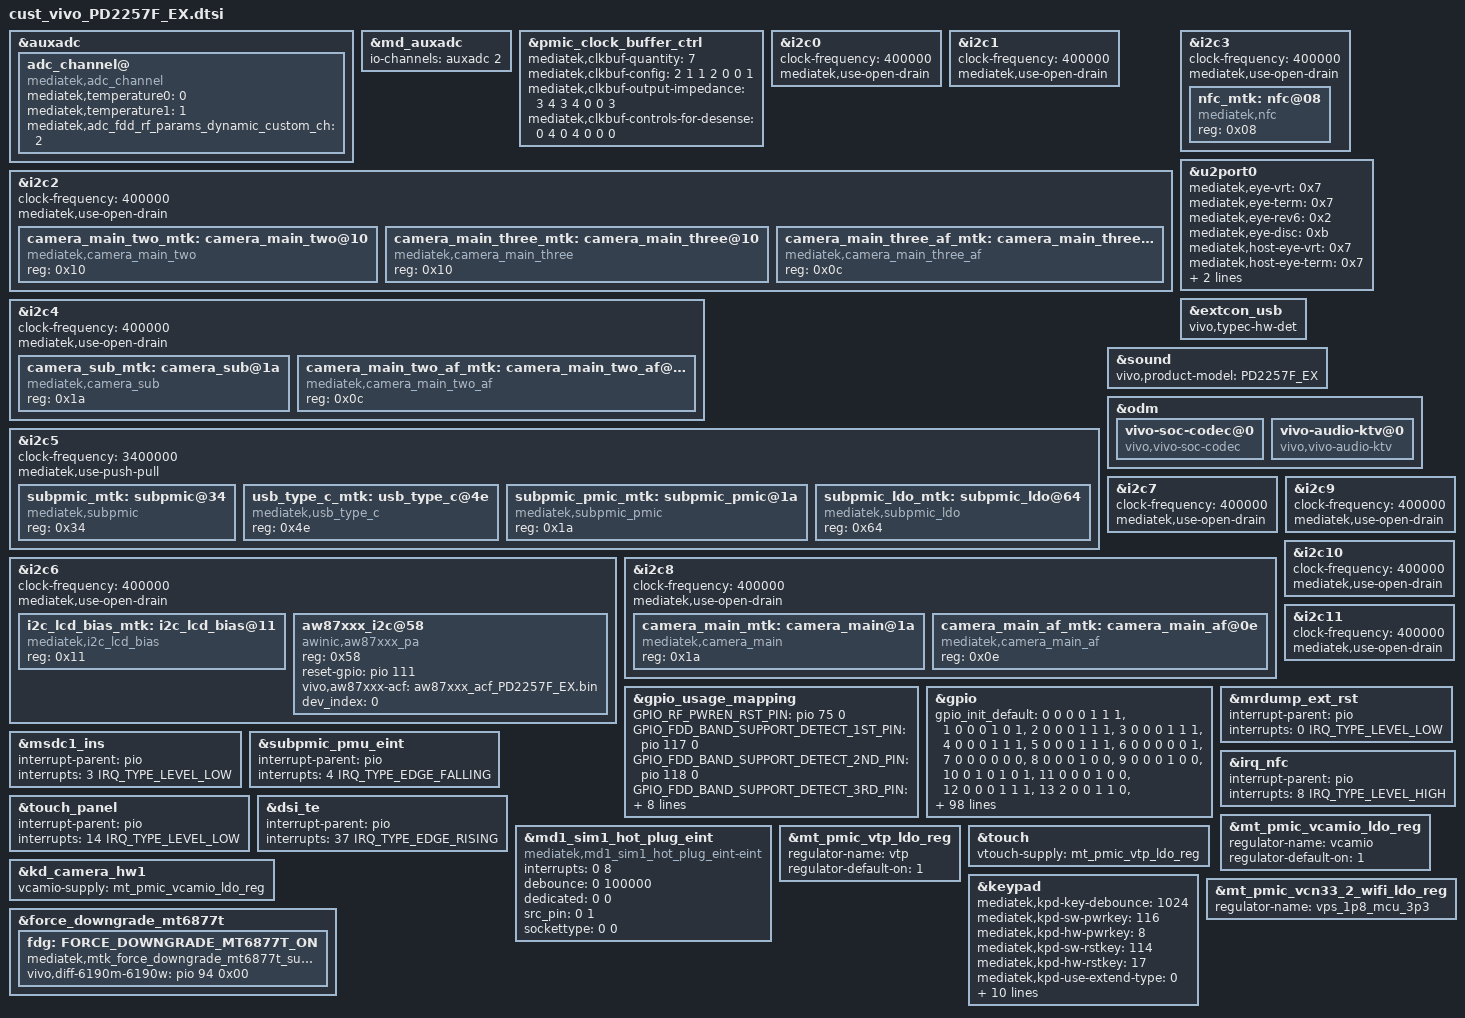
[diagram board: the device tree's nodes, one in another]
/*
	int vbat_mv = batt_volt, vbat_mv_sum = 0, iterm = 0;
 * Generated by MTK SP DrvGen Version: 3.5.160809 for MT6877.
 * 2022-09-20 15:01:34
 * Copyright Mediatek Inc. (c) 2016.
*/

/*************************
 * ADC DTSI File
*************************/
#include <dt-bindings/pinctrl/mt6877-pinfunc.h>

&auxadc {
	adc_channel@ {
		compatible = "mediatek,adc_channel";
		mediatek,temperature0 = <0>;
		mediatek,temperature1 = <1>;
		mediatek,adc_fdd_rf_params_dynamic_custom_ch = <2>;
		status = "okay";
	};
};
&md_auxadc {
	io-channels = <&auxadc 2>;
};


/*************************
 * CLK_BUF DTSI File
*************************/

&pmic_clock_buffer_ctrl {
	mediatek,clkbuf-quantity = <7>;
	mediatek,clkbuf-config = <2 1 1 2 0 0 1>;
	mediatek,clkbuf-output-impedance = <3 4 3 4 0 0 3>;
	mediatek,clkbuf-controls-for-desense = <0 4 0 4 0 0 0>;
	status = "okay";
};


/*************************
 * I2C DTSI File
*************************/

&i2c0 {
	#address-cells = <1>;
	#size-cells = <0>;
	clock-frequency = <400000>;
	mediatek,use-open-drain;
};

&i2c1 {
	#address-cells = <1>;
	#size-cells = <0>;
	clock-frequency = <400000>;
	mediatek,use-open-drain;
};

&i2c2 {
	#address-cells = <1>;
	#size-cells = <0>;
	clock-frequency = <400000>;
	mediatek,use-open-drain;
	camera_main_two_mtk:camera_main_two@10 {
		compatible = "mediatek,camera_main_two";
		reg = <0x10>;
		status = "okay";
	};

	camera_main_three_mtk:camera_main_three@10 {
		compatible = "mediatek,camera_main_three";
		reg = <0x10>;
		status = "okay";
	};

	camera_main_three_af_mtk:camera_main_three_af@0c {
		compatible = "mediatek,camera_main_three_af";
		reg = <0x0c>;
		status = "okay";
	};

};

&i2c3 {
	#address-cells = <1>;
	#size-cells = <0>;
	clock-frequency = <400000>;
	mediatek,use-open-drain;
	nfc_mtk:nfc@08 {
		compatible = "mediatek,nfc";
		reg = <0x08>;
		status = "okay";
	};

};

&i2c4 {
	#address-cells = <1>;
	#size-cells = <0>;
	clock-frequency = <400000>;
	mediatek,use-open-drain;
	camera_sub_mtk:camera_sub@1a {
		compatible = "mediatek,camera_sub";
		reg = <0x1a>;
		status = "okay";
	};

	camera_main_two_af_mtk:camera_main_two_af@0c {
		compatible = "mediatek,camera_main_two_af";
		reg = <0x0c>;
		status = "okay";
	};

};

&i2c5 {
	#address-cells = <1>;
	#size-cells = <0>;
	clock-frequency = <3400000>;
	mediatek,use-push-pull;
	subpmic_mtk:subpmic@34 {
		compatible = "mediatek,subpmic";
		reg = <0x34>;
		status = "okay";
	};

	usb_type_c_mtk:usb_type_c@4e {
		compatible = "mediatek,usb_type_c";
		reg = <0x4e>;
		status = "okay";
	};

	subpmic_pmic_mtk:subpmic_pmic@1a {
		compatible = "mediatek,subpmic_pmic";
		reg = <0x1a>;
		status = "okay";
	};

	subpmic_ldo_mtk:subpmic_ldo@64 {
		compatible = "mediatek,subpmic_ldo";
		reg = <0x64>;
		status = "okay";
	};

};

&i2c6 {
	#address-cells = <1>;
	#size-cells = <0>;
	clock-frequency = <400000>;
	mediatek,use-open-drain;
	i2c_lcd_bias_mtk:i2c_lcd_bias@11 {
		compatible = "mediatek,i2c_lcd_bias";
		reg = <0x11>;
		status = "okay";
	};

};

/* vivo add for usb phy tune begin */
&u2port0 {
	mediatek,eye-vrt = <0x7>;
	mediatek,eye-term = <0x7>;
	mediatek,eye-rev6 = <0x2>;
	mediatek,eye-disc = <0xb>;

	mediatek,host-eye-vrt = <0x7>;
	mediatek,host-eye-term = <0x7>;
	mediatek,host-eye-rev6 = <0x2>;
	mediatek,host-eye-disc = <0xb>;
};

&extcon_usb {
	vivo,typec-hw-det;
};
/* vivo add for usb phy tune end */

/* vivo audio add start */
&sound {
    vivo,product-model = "PD2257F_EX";
};

&odm {
	vivo-soc-codec@0 {
		compatible = "vivo,vivo-soc-codec";
		status = "okay";
	};

	vivo-audio-ktv@0 {
		compatible = "vivo,vivo-audio-ktv";
		status = "okay";
	};
};

&i2c6 {
	aw87xxx_i2c@58 {
		compatible = "awinic,aw87xxx_pa";
		reg = <0x58>;
		reset-gpio = <&pio 111 0>;
		vivo,aw87xxx-acf = "aw87xxx_acf_PD2257F_EX.bin";
		dev_index= <0>;
		status = "okay";
	};
};
/* vivo audio add end */

&i2c7 {
	#address-cells = <1>;
	#size-cells = <0>;
	clock-frequency = <400000>;
	mediatek,use-open-drain;
};

&i2c8 {
	#address-cells = <1>;
	#size-cells = <0>;
	clock-frequency = <400000>;
	mediatek,use-open-drain;
	camera_main_mtk:camera_main@1a {
		compatible = "mediatek,camera_main";
		reg = <0x1a>;
		status = "okay";
	};

	camera_main_af_mtk:camera_main_af@0e {
		compatible = "mediatek,camera_main_af";
		reg = <0x0e>;
		status = "okay";
	};

};

&i2c9 {
	#address-cells = <1>;
	#size-cells = <0>;
	clock-frequency = <400000>;
	mediatek,use-open-drain;
};

&i2c10 {
	#address-cells = <1>;
	#size-cells = <0>;
	clock-frequency = <400000>;
	mediatek,use-open-drain;
};

&i2c11 {
	#address-cells = <1>;
	#size-cells = <0>;
	clock-frequency = <400000>;
	mediatek,use-open-drain;
};



/*************************
 * GPIO DTSI File
*************************/

&gpio_usage_mapping {
	GPIO_RF_PWREN_RST_PIN = <&pio 75 0>;
	GPIO_FDD_BAND_SUPPORT_DETECT_1ST_PIN = <&pio 117 0>;
	GPIO_FDD_BAND_SUPPORT_DETECT_2ND_PIN = <&pio 118 0>;
	GPIO_FDD_BAND_SUPPORT_DETECT_3RD_PIN = <&pio 119 0>;
	GPIO_SIM2_SIO = <&pio 170 0>;
	GPIO_SIM2_SCLK = <&pio 171 0>;
	GPIO_SIM2_SRST = <&pio 172 0>;
	GPIO_SIM1_SRST = <&pio 173 0>;
	GPIO_SIM1_SCLK = <&pio 174 0>;
	GPIO_SIM1_SIO = <&pio 175 0>;
	GPIO_SIM1_HOT_PLUG = <&pio 176 0>;
	//GPIO_SIM2_HOT_PLUG = <&pio 177 0>;
};

&gpio{
	gpio_init_default = <0 0 0 0 1 1 1>,
		<1 0 0 0 1 0 1>,
		<2 0 0 0 1 1 1>,
		<3 0 0 0 1 1 1>,
		<4 0 0 0 1 1 1>,
		<5 0 0 0 1 1 1>,
		<6 0 0 0 0 0 1>,
		<7 0 0 0 0 0 0>,
		<8 0 0 0 1 0 0>,/*pm8008 int*/
		<9 0 0 0 1 0 0>,/*lcm ERR FG*/
		<10 0 1 0 1 0 1>,
		<11 0 0 0 1 0 0>,
		<12 0 0 0 1 1 1>, /* vivo audio modify for headset detect */
		<13 2 0 0 1 1 0>,
		<14 0 0 0 0 0 1>,
		<15 0 1 0 1 0 1>,
		<16 0 1 0 1 0 1>,
		<17 7 0 0 1 0 0>,
		<18 7 0 0 1 1 0>,
		<19 7 0 0 1 0 0>,
		<20 0 0 0 0 0 1>,
		<21 0 1 0 1 0 0>,
		<22 0 0 0 1 0 0>,
		<23 0 0 0 1 0 0>,
		<24 0 0 0 1 1 0>,
		<25 1 0 0 1 0 1>,
		<26 1 0 0 1 1 1>,
		<27 1 0 0 1 0 0>,
		<28 0 0 0 0 0 1>,
		<29 1 0 0 1 1 1>,
		<30 1 0 0 1 0 1>,
		<31 0 0 0 0 0 1>,
		<32 1 0 0 1 0 1>,
		<33 1 1 0 0 0 1>,
		<34 1 0 0 1 0 1>,
		<35 0 0 0 1 1 0>,
		<36 1 0 0 1 1 1>,
		<37 1 0 0 1 1 1>,
		<38 1 0 0 1 0 1>,
		<39 1 0 0 1 0 1>,
		<40 0 1 0 0 0 0>,
		<41 1 0 0 0 0 1>,
		<42 1 0 0 0 0 1>,
		<43 1 0 0 1 0 1>,
		<44 1 0 0 1 0 1>,
		<45 1 0 0 1 1 1>,
		<46 1 0 0 0 0 0>,
		<47 1 0 0 0 0 0>,
		<48 1 0 0 0 0 0>,
		<49 1 0 0 0 0 0>,
		<50 1 0 0 1 0 0>,
		<51 1 0 0 1 0 0>,
		<52 1 0 0 1 0 0>,
		<53 1 0 0 1 0 0>,
		<54 1 0 0 1 0 1>,
		<55 1 0 0 1 0 0>,
		<56 1 0 0 1 0 0>,
		<57 1 0 0 1 0 0>,
		<58 1 0 0 1 0 0>,
		<59 1 0 0 1 0 0>,
		<60 1 0 0 0 0 1>,
		<61 1 0 0 0 0 1>,
		<62 1 0 0 0 0 1>,
		<63 1 0 0 0 0 1>,
		<64 1 0 0 1 1 1>,
		<65 1 0 0 1 1 1>,
		<66 1 0 0 1 0 1>,
		<67 1 0 0 1 0 1>,
		<68 1 0 0 0 0 0>,
		<69 1 0 0 1 0 0>,
		<70 1 0 0 1 0 1>,
		<71 1 0 0 0 0 1>,
		<72 1 0 0 0 0 1>,
		<73 1 0 0 0 0 1>,
		<74 0 0 0 1 1 0>,
		<75 0 1 1 1 0 1>,
		<76 1 0 0 0 0 1>,
		<77 1 0 0 0 0 1>,
		<78 1 0 0 0 0 1>,
		<79 1 0 0 0 0 1>,
		<80 0 0 0 1 1 0>,
		<81 0 0 0 1 1 0>,
		<82 1 0 0 0 0 0>,
		<83 1 0 0 1 0 0>,
		<84 1 0 0 0 0 0>,
		<85 1 0 0 1 0 0>,
		<86 1 0 0 1 0 1>,
		<87 0 0 0 1 1 0>,
		<88 0 0 0 1 1 0>,
		<89 0 0 0 1 1 0>,
		<90 0 0 0 1 1 0>,
		<91 0 0 0 1 1 0>,
		<92 0 0 0 1 1 0>,
		<93 0 0 0 1 1 0>,
		<94 0 0 0 1 1 0>,
		<95 1 0 0 0 0 1>,
		<96 1 0 0 0 0 1>,
		<97 0 0 0 1 1 0>,
		<98 4 0 0 1 1 0>,
		<99 4 0 0 1 1 0>,
		<100 4 0 0 1 1 0>,
		<101 4 0 0 1 1 0>,
		<102 1 0 0 1 1 0>,
		<103 1 0 0 1 1 0>,
		<104 1 0 0 1 1 0>,
		<105 1 0 0 1 1 0>,
		<106 1 0 0 1 1 0>,
		<107 0 1 1 1 0 1>,
		<108 0 1 0 1 0 1>,
		<109 0 1 0 1 0 0>,
		<110 0 1 0 1 0 0>,
		<111 0 1 0 0 0 0>, /* audio PA rst, gpio mode, output-low, no-pull */
		<112 1 0 0 1 1 0>,
		<113 0 0 0 1 1 0>,
		<114 0 0 0 1 0 0>,
		<115 0 1 1 1 0 0>,
		<116 1 0 0 1 1 1>,
		<117 0 0 0 1 0 0>,
		<118 0 0 0 1 0 0>,
		<119 0 0 0 1 0 0>,
		<120 1 0 0 1 0 0>,
		<121 0 0 0 1 0 0>,
		<122 0 1 0 1 0 1>,
		<123 0 1 0 1 0 0>,
		<124 0 1 0 1 0 0>,
		<125 0 1 0 1 0 1>,
		<126 2 0 0 1 0 0>,
		<127 2 0 0 1 0 0>,
		<128 2 0 0 1 1 1>,
		<129 2 0 0 1 0 1>,
		<130 2 0 0 1 1 1>,
		<131 2 0 0 1 1 1>,
		<132 1 0 0 1 1 1>,
		<133 1 0 0 1 1 1>,
		<134 1 0 0 1 1 1>,
		<135 1 0 0 1 1 1>,
		<136 1 0 0 1 1 1>,
		<137 1 0 0 1 1 1>,
		<138 0 1 0 1 0 1>,
		<139 0 1 0 1 0 1>,
		<140 0 0 0 1 0 1>,
		<141 0 0 0 1 0 1>,
		<142 0 1 0 1 0 0>,
		<143 1 0 0 0 0 1>,/*cam0 scl2*/
		<144 1 0 0 0 0 1>,/*cam0 sda2*/
		<145 1 0 0 0 0 1>,/*cam1 scl4*/
		<146 1 0 0 0 0 1>,/*cam1 sda4*/
		<147 1 0 0 1 1 1>,//pm8008 scl9
		<148 1 0 0 1 1 1>,//pm8008 sda9
		<149 1 1 0 0 0 0>,/*cam0 clk0*/
		<150 1 1 0 0 0 0>,/*cam1 clk1*/
		<151 1 1 0 0 0 0>,/*cam2 clk2*/
		<152 1 1 0 0 0 0>,/*cam3 clk3*/
		<153 0 0 0 1 0 0>,
		<154 0 0 0 1 0 0>,
		<155 0 0 0 1 1 0>,
		<156 0 0 0 1 1 0>,
		<157 0 0 0 1 1 0>,
		<158 0 0 0 1 0 0>,
		<159 0 0 0 1 1 0>,
		<160 0 0 0 1 0 0>,
		<161 0 0 0 1 0 0>,
		<162 0 0 0 1 0 0>,
		<163 0 0 0 1 1 1>,
		<164 1 0 0 1 1 0>,
		<165 1 0 0 0 0 0>,
		<166 1 0 0 1 1 0>,
		<167 1 0 0 1 1 0>,
		<168 1 0 0 1 1 0>,
		<169 1 0 0 1 1 0>,
		<170 1 0 0 1 1 1>,
		<171 1 0 0 0 0 1>,
		<172 1 0 0 0 0 1>,
		<173 1 0 0 0 0 1>,
		<174 1 0 0 0 0 1>,
		<175 1 0 0 1 1 1>,
		<176 1 0 0 1 1 1>,
		<177 1 0 0 1 0 1>,
		<178 1 0 0 1 0 0>,
		<179 1 0 0 1 0 0>,
		<180 1 0 0 1 1 1>,
		<181 1 0 0 1 1 1>,
		<182 1 0 0 1 1 0>,
		<183 1 0 0 1 1 0>,
		<184 1 0 0 0 0 0>,
		<185 1 0 0 1 1 0>,
		<186 1 0 0 1 1 1>,
		<187 1 0 0 1 1 1>,
		<188 0 1 0 1 0 0>,
		<189 0 1 0 1 0 0>,
		<190 1 0 0 1 1 0>,
		<191 1 0 0 1 1 0>,
		<192 1 0 0 1 0 0>,
		<193 0 0 0 1 1 0>,
		<194 0 0 0 1 1 0>,
		<195 0 0 0 1 0 0>,
		<196 0 0 0 1 0 0>,
		<197 0 0 0 1 0 0>,
		<198 0 0 0 1 0 0>,
		<199 0 0 0 1 0 0>,
		<200 0 0 0 1 0 0>,
		<201 0 0 0 1 0 0>,
		<202 0 0 0 1 0 0>,
		<203 0 0 0 1 0 0>,
		<204 0 0 0 1 0 0>,
		<205 0 0 0 1 0 0>,
		<206 0 0 0 1 0 0>,
		<207 0 0 0 1 0 0>,
		<208 0 0 0 1 0 0>;
};


/*************************
 * EINT DTSI File
*************************/

#include <dt-bindings/interrupt-controller/irq.h>
#include <dt-bindings/interrupt-controller/arm-gic.h>

&mrdump_ext_rst {
	interrupt-parent = <&pio>;
	interrupts = <0 IRQ_TYPE_LEVEL_LOW>;
	status = "okay";
};

&msdc1_ins {
	interrupt-parent = <&pio>;
	interrupts = <3 IRQ_TYPE_LEVEL_LOW>;
	status = "okay";
};

&subpmic_pmu_eint {
	interrupt-parent = <&pio>;
	interrupts = <4 IRQ_TYPE_EDGE_FALLING>;
	status = "okay";
};

&irq_nfc {
	interrupt-parent = <&pio>;
	interrupts = <8 IRQ_TYPE_LEVEL_HIGH>;
	status = "okay";
};

&touch_panel {
	interrupt-parent = <&pio>;
	interrupts = <14 IRQ_TYPE_LEVEL_LOW>;
	status = "okay";
};

&dsi_te {
	interrupt-parent = <&pio>;
	interrupts = <37 IRQ_TYPE_EDGE_RISING>;
	status = "okay";
};



/*************************
 * MD1_EINT DTSI File
*************************/

&md1_sim1_hot_plug_eint {
	compatible = "mediatek,md1_sim1_hot_plug_eint-eint";
	interrupts = <0 8>;
	debounce = <0 100000>;
	dedicated = <0 0>;
	src_pin = <0 1>;
	sockettype = <0 0>;
	status = "okay";
};



/*************************
 * PMIC DTSI File
*************************/

&mt_pmic_vcamio_ldo_reg {
	regulator-name = "vcamio";
	regulator-default-on = <1>; /* 0:skip, 1: off, 2:on */
	status = "okay";
};
&mt_pmic_vtp_ldo_reg {
	regulator-name = "vtp";
	regulator-default-on = <1>; /* 0:skip, 1: off, 2:on */
	status = "okay";
};

&kd_camera_hw1 {
	vcamio-supply = <&mt_pmic_vcamio_ldo_reg>;
	status = "okay";
};

&touch {
	vtouch-supply = <&mt_pmic_vtp_ldo_reg>;
	status = "okay";
};


/*************************
 * POWER DTSI File
*************************/



/*************************
 * KPD DTSI File
*************************/

&keypad {
	mediatek,kpd-key-debounce = <1024>;
	mediatek,kpd-sw-pwrkey = <116>;
	mediatek,kpd-hw-pwrkey = <8>;
	mediatek,kpd-sw-rstkey  = <114>;
	mediatek,kpd-hw-rstkey = <17>;
	mediatek,kpd-use-extend-type = <0>;
	/*HW Keycode [0~71] -> Linux Keycode*/
	mediatek,kpd-hw-map-num = <72>;
	mediatek,kpd-hw-init-map = <115 0 0 0 0 0 0 0 0 0 0 0 0 0 0 0 0 0 0 0 0 0 0 0 0 0 0 0 0 0 0 0 0 0 0 0 0 0 0 0 0 0 0 0 0 0 0 0 0 0 0 0 0 0 0 0 0 0 0 0 0 0 0 0 0 0 0 0 0 0 0 0 >;
	mediatek,kpd-pwrkey-eint-gpio = <0>;
	mediatek,kpd-pwkey-gpio-din  = <0>;
	mediatek,kpd-hw-dl-key0 = <17>;
	mediatek,kpd-hw-dl-key1 = <0>;
	mediatek,kpd-hw-dl-key2 = <8>;
	mediatek,kpd-hw-recovery-key = <17>;
	mediatek,kpd-hw-factory-key = <0>;
	status = "okay";
};

&mt_pmic_vcn33_2_wifi_ldo_reg {
	regulator-name = "vps_1p8_mcu_3p3";
};

/* force downgrade mt6877T*/
&force_downgrade_mt6877t {
	fdg: FORCE_DOWNGRADE_MT6877T_ON {
		compatible = "mediatek,mtk_force_downgrade_mt6877t_support";
		vivo,diff-6190m-6190w = <&pio 94 0x00>;
	};
};
